# R7FA6T2BD register map
Vendor: Renesas Electronics Corporation; Series: RA6; File version: 1.40.00
CPU: CM33 r0p4, little endian, MPU, FPU, VTOR, 4 interrupt priority bits, 96 interrupts
Registers are 32-bit, read-write, reset 0x0 unless marked. A register's access mark holds for its fields unless they carry their own. Offsets are from the block's base; [hi:lo] are bit positions.

## IIC0WU_B — Inter-Integrated Circuit 0 Wake-up Unit
Base 0x4011F098
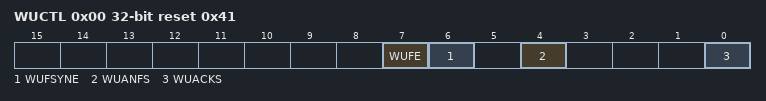
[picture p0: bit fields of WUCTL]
0x00 WUCTL reset 0x41 — Wake Up Unit Control Register
  [7] WUFE — Wake-Up function Enable
    0=Wake-up function disables; 1=Wake-up function enables
  [6] WUFSYNE — Wake-Up function PCLKA Synchronous Enable
    0=IIC asynchronous circuit enable; 1=IIC synchronous circuit enable
  [4] WUANFS — Wake-Up Analog Noise Filter Selection
    0=Do not add the Wake Up analog filter; 1=Add the Wake Up analog filter
  [0] WUACKS — Wake-Up Acknowledge Selection
0x180 WUST ro — Wake Up Unit Operating Status Register
  [0] WUASYNF — Wake-up function asynchronous operation status flag
    0=IIC synchronous circuit enable condition; 1=IIC asynchronous circuit enable condition

## ECCMB — CANFD ECC Module
Base 0x4012F200
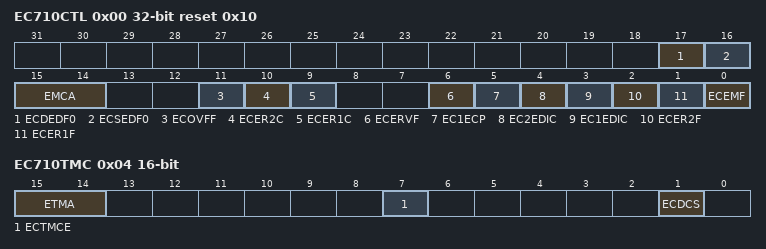
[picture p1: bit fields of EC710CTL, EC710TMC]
0x00 EC710CTL reset 0x10 — ECC Control Register
  [17] ECDEDF0 ro — ECC Dual Bit Error Address Detection Flag
    0=There is no bit error in EC710EAD0 after reset or clearing ECER2F bit; 1=Address captured in EC710EAD0 shows that 2-bit error occurred and captured
  [16] ECSEDF0 ro — ECC Single bit Error Address Detection Flag
    0=There is no bit error in EC710EAD0 after reset or clearing ECER1F bit; 1=Address captured in EC710EAD0 shows that 1-bit error occurred and captured
  [15:14] EMCA — Access Control to ECC Mode Select bit
  [11] ECOVFF ro — ECC Overflow Detection Flag
    0=No effect; 1=ECC overflow detection flag
  [10] ECER2C — 2-bit ECC Error Detection Flag Clear
    0=No effect; 1=Clear 2-bit ECC error detection flag
  [9] ECER1C — Accumulating ECC Error Detection and Correction Flag Clear
    0=No effect; 1=Clear accumulating ECC error detection and correction flag
  [6] ECERVF — ECC Error Judgment Enable Flag
    0=Error judgment disable; 1=Error judgment enable
  [5] EC1ECP — ECC 1-bit Error Correction Permission
    0=At 1-bit error detection, the error correction is executed; 1=At 1-bit error detection, the error correction is not executed
  [4] EC2EDIC — ECC 2-bit Error Detection Interrupt Control
    0=Disable 2-bit error detection interrupt request; 1=Enable 2-bit error detection interrupt request
  [3] EC1EDIC — ECC 1-bit Error Detection Interrupt Control
    0=Disable 1-bit error detection interrupt request; 1=Enable 1-bit error detection interrupt request
  [2] ECER2F ro — 2-bit ECC Error Detection Flag
    0=After clearing this bit, 2-bit error has not occurred; 1=2-bit error has occurred
  [1] ECER1F ro — ECC Error Detection and Correction Flag
    0=After clearing this bit, 1-bit error correction has not occurred; 1=1-bit error has occurred
  [0] ECEMF ro — ECC Error Message Flag
    0=There is no bit error in present RAM output data; 1=There is bit error in present RAM output data
0x04 EC710TMC 16-bit — ECC Test Mode Control Register
  [15:14] ETMA — ECC Test Mode Bit Access Control
  [7] ECTMCE — ECC Test Mode Control Enable
    0=The access to test mode register and bit is disabled; 1=The access to test mode register and bit is enabled
  [1] ECDCS — ECC Decode Input Select
    0=Input lower 32 bits of RAM output data to data area of decode circuit; 1=Input ECEDB31-0 in EC710TED register to data area of decode circuit
0x0C EC710TED — ECC Test Substitute Data Register
  [31:0] ECEDB — ECC Test Substitute Data
0x10 EC710EAD0 ro — ECC Error Address Register
  [10:0] ECEAD — ECC Error Address

## GPT_OPS — Output Phase Switching Controller
Base 0x40169A00
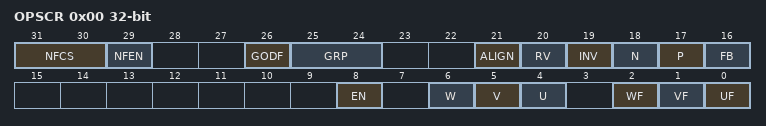
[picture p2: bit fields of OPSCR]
0x00 OPSCR — Output Phase Switching Control Register
  [31:30] NFCS — External Input Noise Filter Clock Selection
    0=GTCLK/1; 1=GTCLK/4; 2=GTCLK/16; 3=GTCLK/64
  [29] NFEN — External Input Noise Filter Enable
    0=Do not use a noise filter on the external input; 1=Use a noise filter on the external input
  [26] GODF — Group Output Disable Function
    0=This bit function is ignored; 1=Group disable clears the OPSCR.EN bit
  [25:24] GRP — Output Disabled Source Selection
  [21] ALIGN — Input Phase Alignment
    0=Input phase aligned to GTCLK; 1=Input phase aligned to the falling edge of PWM
  [20] RV — Output Phase Rotation Direction Reversal Control
    0=Positive rotation; 1=Reverse rotation
  [19] INV — Output Phase Invert Control
    0=Positive logic (active-high) output; 1=Negative logic (active-low) output
  [18] N — Negative-Phase Output (N) Control
    0=Level signal output; 1=PWM signal output
  [17] P — Positive-Phase Output (P) Control
    0=Level signal output; 1=PWM signal output
  [16] FB — External Feedback Signal Enable
    0=Select the external input; 1=Select the soft setting (OPSCR.UF, VF, WF)
  [8] EN — Output Phase Enable
    0=Do not output (Hi-Z external pin); 1=Output
  [6] W ro — Input W-Phase Monitor
  [5] V ro — Input V-Phase Monitor
  [4] U ro — Input U-Phase Monitor
  [2] WF
  [1] VF
  [0] UF
